AUTOSAR XML (schema 4-3-0)
package /ABSMalfunctionDetectionSystem
  system ABSSystem  # ABS Malfunction Detection System | Complete system for detecting ABS malfunctions from miscalibrated speed sensors
    sw-mappings:
      swc to ecu mapping SpeedSensorSwcMapping: ecu-instance=ABS_ECU, component=RootComposition.SpeedSensorSwcPrototype
      swc to ecu mapping ABSMalfunctionDetectionSwcMapping: ecu-instance=ABS_ECU, component=RootComposition.ABSMalfunctionDetectionSwcPrototype
    ecu instance ABS_ECU: ecu-instance-props=wake-up-over-bus-supported=true
    root sw composition prototype RootComposition: software-composition=ABSComposition
package /Compositions
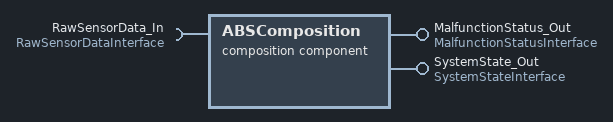
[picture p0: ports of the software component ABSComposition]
  composition sw component type ABSComposition  # ABS Malfunction Detection Composition | Composition containing speed sensor and malfunction detection components
    4 x component:
      SpeedSensorSwcPrototype: type=SpeedSensorSwc
      ABSMalfunctionDetectionSwcPrototype: type=ABSMalfunctionDetectionSwc
      CalibrationManagerPrototype: type=CalibrationManagerSwc
      DiagnosticServicePrototype: type=DiagnosticServiceSwc
    connect SpeedSensorSwcPrototype.SpeedData_FL -> ABSMalfunctionDetectionSwcPrototype.SpeedData_FL_In
    connect SpeedSensorSwcPrototype.SpeedData_FR -> ABSMalfunctionDetectionSwcPrototype.SpeedData_FR_In
    connect SpeedSensorSwcPrototype.SpeedData_RL -> ABSMalfunctionDetectionSwcPrototype.SpeedData_RL_In
    connect SpeedSensorSwcPrototype.SpeedData_RR -> ABSMalfunctionDetectionSwcPrototype.SpeedData_RR_In
    connect SpeedSensorSwcPrototype.CalibrationService -> CalibrationManagerPrototype.CalibrationService_R
    provide port MalfunctionStatus_Out: provided-interface=MalfunctionStatusInterface
    provide port SystemState_Out: provided-interface=SystemStateInterface
    require port RawSensorData_In: required-interface=RawSensorDataInterface
    delegate ABSMalfunctionDetectionSwcPrototype.MalfunctionStatus_FL <-> outer port MalfunctionStatus_Out
    delegate ABSMalfunctionDetectionSwcPrototype.SystemState <-> outer port SystemState_Out
    delegate SpeedSensorSwcPrototype.RawSensorData_FL <-> outer port RawSensorData_In
package /ServiceComponents
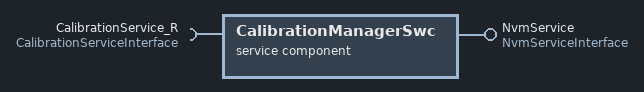
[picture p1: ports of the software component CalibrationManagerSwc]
  service sw component type CalibrationManagerSwc  # Calibration Manager Service Component | Service component for managing speed sensor calibration
    require port CalibrationService_R: required-interface=CalibrationServiceInterface
    provide port NvmService: provided-interface=NvmServiceInterface
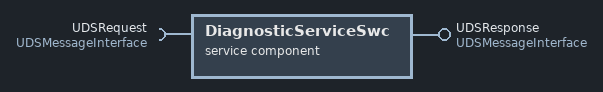
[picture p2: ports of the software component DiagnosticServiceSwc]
  service sw component type DiagnosticServiceSwc  # Diagnostic Service Component | Service component for UDS diagnostic services and DTC management
    require port UDSRequest: required-interface=UDSMessageInterface
    provide port UDSResponse: provided-interface=UDSMessageInterface
